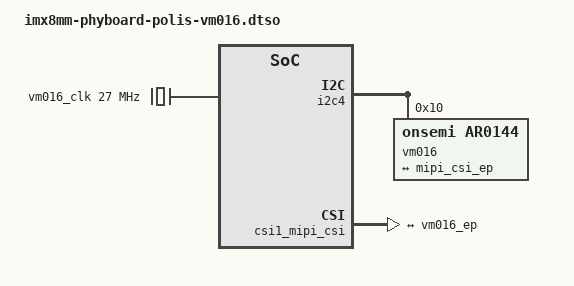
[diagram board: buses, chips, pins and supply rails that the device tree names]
// SPDX-License-Identifier: (GPL-2.0+ OR MIT)
/*
 * Copyright (C) 2025 PHYTEC Messtechnik GmbH
 * Author: Stefan Riedmüller <s.riedmueller@phytec.de>
 */

/dts-v1/;
/plugin/;

&{/} {
	vm016_clk: vm016-ext-clk {
		#clock-cells = <0>;
		compatible = "fixed-clock";
		clock-frequency = <27000000>;
	};
};

&i2c4 {
	#address-cells = <1>;
	#size-cells = <0>;

	vm016: camera@10 {
		#address-cells = <0x1>;
		#size-cells = <0x0>;

		compatible = "onsemi,ar0144";
		reg = <0x10>;
		clocks = <&vm016_clk>;
		clock-names = "ext";

		port@0 {
			reg = <0>;

			vm016_ep: endpoint {
				remote-endpoint = <&mipi_csi_ep>;
				bus-type = <4>; /* MIPI CSI-2 D-PHY */
				link-frequencies = /bits/ 64 <222750000>;
				data-lanes = <1 2>;
				clock-lanes = <0>;
				clock-noncontinuous = <1>;
				onsemi,t-hs-prep = <1>;
				onsemi,t-clk-post = <9>;
			};
		};
	};
};

&csi1_mipi_csi {
	status = "okay";

	ports {
		#address-cells = <1>;
		#size-cells = <0>;

		port@0 {
			reg = <0>;
			mipi_csi_ep: endpoint {
				remote-endpoint = <&vm016_ep>;
				data-lanes = <1 2>;
			};
		};
	};
};
